# MKW30Z4 register map
Vendor: Freescale Semiconductor, Inc.; Series: Kinetis_W; File version: 1.6
CPU: CM0PLUS r0p0, little endian, no MPU, no FPU, VTOR, 2 interrupt priority bits
Registers are 32-bit, read-write, reset 0x0 unless marked. A register's access mark holds for its fields unless they carry their own. Offsets are from the block's base; [hi:lo] are bit positions.

## I2C0 — Inter-Integrated Circuit
Base 0x40066000; register names take the prefix I2C0_
0x00 A1 8-bit — I2C Address Register 1
  [7:1] AD — Address
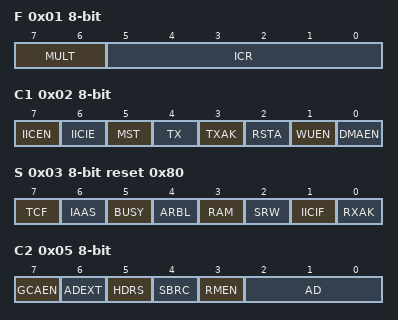
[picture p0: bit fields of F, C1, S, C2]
0x01 F 8-bit — I2C Frequency Divider register
  [7:6] MULT — Multiplier Factor
    0=mul = 1; 1=mul = 2; 2=mul = 4
  [5:0] ICR — ClockRate
0x02 C1 8-bit — I2C Control Register 1
  [7] IICEN — I2C Enable
    0=Disabled; 1=Enabled
  [6] IICIE — I2C Interrupt Enable
    0=Disabled; 1=Enabled
  [5] MST — Master Mode Select
    0=Slave mode; 1=Master mode
  [4] TX — Transmit Mode Select
    0=Receive; 1=Transmit
  [3] TXAK — Transmit Acknowledge Enable
    0=An acknowledge signal is sent to the bus on the following receiving byte (if FACK is cleared) or the current receiving byte (if FACK is set); 1=No acknowledge signal is sent to the bus on the following receiving data byte (if FACK is cleared) or the current receiving data byte (if FACK is set)
  [2] RSTA wo — Repeat START
  [1] WUEN — Wakeup Enable
    0=Normal operation. No interrupt generated when address matching in low power mode.; 1=Enables the wakeup function in low power mode
  [0] DMAEN — DMA Enable
    0=All DMA signalling disabled; 1=DMA transfer is enabled. While SMB[FACK] = 0, the following conditions trigger the DMA request: a data byte is received, and either address or data is transmitted. (ACK/NACK is automatic) the first byte received matches the A1 register or is a general call address. If any address matching occurs, S[IAAS] and S[TCF] are set. If the direction of transfer is known from master to slave, then it is not required to check S[SRW]. With this assumption, DMA can also be used in this case. In other cases, if the master reads data from the slave, then it is required to rewrite the C1 register operation. With this assumption, DMA cannot be used. When FACK = 1, an address or a data byte is transmitted.
0x03 S 8-bit reset 0x80 — I2C Status register
  [7] TCF ro — Transfer Complete Flag
    0=Transfer in progress; 1=Transfer complete
  [6] IAAS — Addressed As A Slave
    0=Not addressed; 1=Addressed as a slave
  [5] BUSY ro — Bus Busy
    0=Bus is idle; 1=Bus is busy
  [4] ARBL — Arbitration Lost
    0=Standard bus operation; 1=Loss of arbitration
  [3] RAM — Range Address Match
    0=Not addressed; 1=Addressed as a slave
  [2] SRW ro — Slave Read/Write
    0=Slave receive, master writing to slave; 1=Slave transmit, master reading from slave
  [1] IICIF — Interrupt Flag
    0=No interrupt pending; 1=Interrupt pending
  [0] RXAK ro — Receive Acknowledge
    0=Acknowledge signal was received after the completion of one byte of data transmission on the bus; 1=No acknowledge signal detected
0x04 D 8-bit — I2C Data I/O register
  [7:0] DATA
0x05 C2 8-bit — I2C Control Register 2
  [7] GCAEN — General Call Address Enable
    0=Disabled; 1=Enabled
  [6] ADEXT — Address Extension
    0=7-bit address scheme; 1=10-bit address scheme
  [5] HDRS — High Drive Select
    0=Normal drive mode; 1=High drive mode
  [4] SBRC — Slave Baud Rate Control
    0=The slave baud rate follows the master baud rate and clock stretching may occur; 1=Slave baud rate is independent of the master baud rate
  [3] RMEN — Range Address Matching Enable
    0=Range mode disabled. No address matching occurs for an address within the range of values of the A1 and RA registers.; 1=Range mode enabled. Address matching occurs when a slave receives an address within the range of values of the A1 and RA registers.
  [2:0] AD — Slave Address
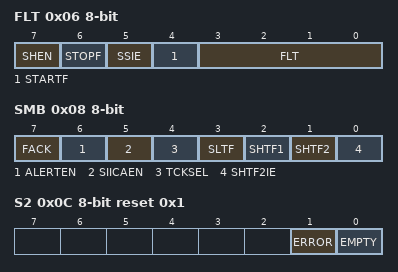
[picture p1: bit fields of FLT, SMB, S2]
0x06 FLT 8-bit — I2C Programmable Input Glitch Filter Register
  [7] SHEN — Stop Hold Enable
    0=Stop holdoff is disabled. The MCU's entry to stop mode is not gated. Clocks to peripherals are gated when the core stop occurs.; 1=Stop holdoff is enabled. Stop mode entry is gated until the current transaction phase is complete, and the IP enters stop mode (clocks are gated) after the current phase's completion. That is to say: If the system stop request occurs between the address or data phase, the stop acknowledge is asserted after the current byte and IIC ack completion (after the acknowledge in the ninth cycle).
  [6] STOPF — I2C Bus Stop Detect Flag
    0=No stop happens on I2C bus; 1=Stop detected on I2C bus
  [5] SSIE — I2C Bus Stop or Start Interrupt Enable
    0=Stop or start detection interrupt is disabled; 1=Stop or start detection interrupt is enabled
  [4] STARTF — I2C Bus Start Detect Flag
    0=No start happens on I2C bus; 1=Start detected on I2C bus
  [3:0] FLT — I2C Programmable Filter Factor
    0=No filter/bypass
0x07 RA 8-bit — I2C Range Address register
  [7:1] RAD — Range Slave Address
0x08 SMB 8-bit — I2C SMBus Control and Status register
  [7] FACK — Fast NACK/ACK Enable
    0=An ACK or NACK is sent on the following receiving data byte; 1=Writing 0 to TXAK after receiving a data byte generates an ACK. Writing 1 to TXAK after receiving a data byte generates a NACK.
  [6] ALERTEN — SMBus Alert Response Address Enable
    0=SMBus alert response address matching is disabled; 1=SMBus alert response address matching is enabled
  [5] SIICAEN — Second I2C Address Enable
    0=I2C address register 2 matching is disabled; 1=I2C address register 2 matching is enabled
  [4] TCKSEL — Timeout Counter Clock Select
    0=Timeout counter counts at the frequency of the I2C module clock / 64; 1=Timeout counter counts at the frequency of the I2C module clock
  [3] SLTF — SCL Low Timeout Flag
    0=No low timeout occurs; 1=Low timeout occurs
  [2] SHTF1 ro — SCL High Timeout Flag 1
    0=No SCL high and SDA high timeout occurs; 1=SCL high and SDA high timeout occurs
  [1] SHTF2 — SCL High Timeout Flag 2
    0=No SCL high and SDA low timeout occurs; 1=SCL high and SDA low timeout occurs
  [0] SHTF2IE — SHTF2 Interrupt Enable
    0=SHTF2 interrupt is disabled; 1=SHTF2 interrupt is enabled
0x09 A2 8-bit reset 0xC2 — I2C Address Register 2
  [7:1] SAD — SMBus Address
0x0A SLTH 8-bit — I2C SCL Low Timeout Register High
  [7:0] SSLT — SSLT[15:8]
0x0B SLTL 8-bit — I2C SCL Low Timeout Register Low
  [7:0] SSLT — SSLT[7:0]
0x0C S2 8-bit reset 0x1 — I2C Status register 2
  [1] ERROR — Error flag
    0=The buffer is not full and all write/read operations have no errors; 1=There are 3 or more write/read errors during the data transfer phase (when the Empty flag is not set and the buffer is busy)
  [0] EMPTY ro — Empty flag
    0=Tx or Rx buffer is not empty and cannot be written to, that is new data cannot be loaded into the buffer; 1=Tx or Rx buffer is empty and can be written to, that is new data can be loaded into the buffer. Write 1 to reset this flag (to the default value 1, which means that the Tx or Rx buffer is empty).

## I2C1 — Inter-Integrated Circuit
Base 0x40067000; register names take the prefix I2C1_
Registers as I2C0.
